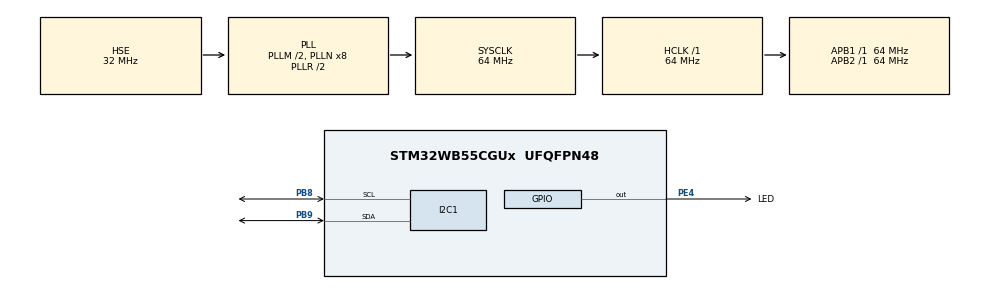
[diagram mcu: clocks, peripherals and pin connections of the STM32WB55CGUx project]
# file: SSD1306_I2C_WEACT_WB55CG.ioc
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Dma.I2C1_TX.0.Direction=DMA_MEMORY_TO_PERIPH
Dma.I2C1_TX.0.EventEnable=DISABLE
Dma.I2C1_TX.0.Instance=DMA1_Channel6
Dma.I2C1_TX.0.MemDataAlignment=DMA_MDATAALIGN_BYTE
Dma.I2C1_TX.0.MemInc=DMA_MINC_ENABLE
Dma.I2C1_TX.0.Mode=DMA_NORMAL
Dma.I2C1_TX.0.PeriphDataAlignment=DMA_PDATAALIGN_BYTE
Dma.I2C1_TX.0.PeriphInc=DMA_PINC_DISABLE
Dma.I2C1_TX.0.Polarity=HAL_DMAMUX_REQ_GEN_RISING
Dma.I2C1_TX.0.Priority=DMA_PRIORITY_LOW
Dma.I2C1_TX.0.RequestNumber=1
Dma.I2C1_TX.0.SignalID=NONE
Dma.I2C1_TX.0.SyncEnable=DISABLE
Dma.I2C1_TX.0.SyncPolarity=HAL_DMAMUX_SYNC_NO_EVENT
Dma.I2C1_TX.0.SyncRequestNumber=1
Dma.I2C1_TX.0.SyncSignalID=NONE
Dma.Request0=I2C1_TX
I2C1.Timing=0x10B17DB5
Mcu.Family=STM32WB
Mcu.Name=STM32WB55CGUx
Mcu.Package=UFQFPN48
NVIC.DMA1_Channel6_IRQn=true\:0\:0\:false\:false\:true\:false\:true\:true
NVIC.I2C1_EV_IRQn=true\:0\:0\:false\:false\:true\:true\:true\:true
NVIC.PriorityGroup=NVIC_PRIORITYGROUP_4
NVIC.TIM2_IRQn=true\:15\:0\:false\:false\:true\:false\:true\:true
NVIC.TimeBase=TIM2_IRQn
NVIC.TimeBaseIP=TIM2
OSC_IN.Mode=HSE-External-Oscillator
OSC_IN.Signal=RCC_OSC_IN
OSC_OUT.Mode=HSE-External-Oscillator
OSC_OUT.Signal=RCC_OSC_OUT
PB8.GPIO_Speed=GPIO_SPEED_FREQ_VERY_HIGH
PB8.Mode=I2C
PB8.Signal=I2C1_SCL
PB9.GPIO_Speed=GPIO_SPEED_FREQ_VERY_HIGH
PB9.Mode=I2C
PB9.Signal=I2C1_SDA
PC14-OSC32_IN.Mode=LSE-External-Oscillator
PC14-OSC32_IN.Signal=RCC_OSC32_IN
PC15-OSC32_OUT.Mode=LSE-External-Oscillator
PC15-OSC32_OUT.Signal=RCC_OSC32_OUT
PE4.GPIO_Label=LED
PE4.Signal=GPIO_Output
ProjectManager.HeapSize=0x200
ProjectManager.StackSize=0x400
ProjectManager.TargetToolchain=STM32CubeIDE
RCC.ADCFreq_Value=64000000
RCC.AHB2CLKDivider=RCC_SYSCLK_DIV2
RCC.AHBFreq_Value=64000000
RCC.APB1Freq_Value=64000000
RCC.APB1TimFreq_Value=64000000
RCC.APB2Freq_Value=64000000
RCC.APB2TimFreq_Value=64000000
RCC.APB3Freq_Value=16000000
RCC.Cortex2_Div=SYSTICK_CLKSOURCE_HCLK_DIV8
RCC.CortexFreq_Value=64000000
RCC.HCLKFreq_Value=64000000
RCC.HSE_VALUE=32000000
RCC.HSI48_VALUE=48000000
RCC.HSI_VALUE=16000000
RCC.PLLM=RCC_PLLM_DIV2
RCC.PLLSourceVirtual=RCC_PLLSOURCE_HSE
RCC.RTCClockSelection=RCC_RTCCLKSOURCE_LSE
RCC.SYSCLKFreq_VALUE=64000000
RCC.SYSCLKSource=RCC_SYSCLKSOURCE_PLLCLK
RCC.USBFreq_Value=64000000
RCC.VCOOutputFreq_Value=128000000
RTC.Date=20
RTC.Hours=1
RTC.Minutes=15
RTC.Month=RTC_MONTH_JUNE
RTC.WeekDay=RTC_WEEKDAY_SATURDAY
RTC.Year=26
VP_MEMORYMAP_VS_MEMORYMAP.Mode=CurAppReg
VP_RTC_VS_RTC_Activate.Mode=RTC_Enabled
VP_RTC_VS_RTC_Calendar.Mode=RTC_Calendar
VP_SYS_VS_tim2.Mode=TIM2
board=custom

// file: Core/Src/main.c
/* USER CODE BEGIN Header */
/**
  ******************************************************************************
  * @file           : main.c
  * @brief          : Main program body
  ******************************************************************************
  * @attention
  *
  * Copyright (c) 2026 STMicroelectronics.
  * All rights reserved.
  *
  * This software is licensed under terms that can be found in the LICENSE file
  * in the root directory of this software component.
  * If no LICENSE file comes with this software, it is provided AS-IS.
  *
  ******************************************************************************
  */
/* USER CODE END Header */
#include "main.h"

/* USER CODE BEGIN Includes */
#include <stdio.h>
#include "ssd1306.h"
/* USER CODE END Includes */

/* USER CODE BEGIN PD */
volatile uint8_t rast = 0;
/* USER CODE END PD */

I2C_HandleTypeDef hi2c1;
DMA_HandleTypeDef hdma_i2c1_tx;

RTC_HandleTypeDef hrtc;

void SystemClock_Config(void);
void PeriphCommonClock_Config(void);
static void MX_GPIO_Init(void);
static void MX_DMA_Init(void);
static void MX_I2C1_Init(void);
static void MX_RTC_Init(void);
/* USER CODE BEGIN PFP */
void ssd1306_RasterIntCallback(uint8_t r);
static void LED_Blink(uint32_t Hdelay,uint32_t Ldelay);
/* USER CODE END PFP */

int main(void)
{

  /* MCU Configuration--------------------------------------------------------*/

  /* Reset of all peripherals, Initializes the Flash interface and the Systick. */
  HAL_Init();

  /* Configure the system clock */
  SystemClock_Config();

  /* Configure the peripherals common clocks */
  PeriphCommonClock_Config();

  /* Initialize all configured peripherals */
  MX_GPIO_Init();
  MX_DMA_Init();
  MX_I2C1_Init();
  MX_RTC_Init();

  /* Infinite loop */
  /* USER CODE BEGIN WHILE */
  ssd1306_Init();

  // ------ Text Demo ------
  ssd1306_Clear();

  ssd1306_SetColor(White);

  ssd1306_SetCursor(0, 0);
  ssd1306_WriteString("SSD1306 DEMO", Font_7x10);

  ssd1306_SetCursor(0, 16);
  ssd1306_WriteString("Hello World!", Font_7x10);

  ssd1306_SetCursor(0, 32);
  ssd1306_WriteString("STM32 OLED", Font_7x10);

  ssd1306_UpdateScreen();

  HAL_Delay(1000);

  // ------ Shape Demo ------
  ssd1306_Clear();
  ssd1306_SetColor(White);

  // Rectangle outline
  ssd1306_DrawRect(2, 2, 40, 20);

  // Filled rectangle
  ssd1306_FillRect(50, 2, 40, 20);

  // Circle
  ssd1306_DrawCircle(30, 50, 10);

  // Filled circle
  ssd1306_FillCircle(90, 50, 10);

  // Triangle
  ssd1306_DrawTriangle(10, 60, 30, 40, 50, 60);

  ssd1306_UpdateScreen();

  HAL_Delay(1000);

  // ----- Line Demo ------
  ssd1306_Clear();
  ssd1306_SetColor(White);

  // Horizontal line
  ssd1306_DrawHorizontalLine(0, 10, 128);

  // Vertical line
  ssd1306_DrawVerticalLine(64, 0, 64);

  // Diagonal line
  ssd1306_DrawLine(0, 63, 127, 0);

  ssd1306_UpdateScreen();

  HAL_Delay(1000);

  // ----- Animation ------
  ssd1306_Clear();
  ssd1306_SetColor(White);

  for (uint8_t i = 0; i <= 100; i++)
  {
      // progress bar di tengah layar
      ssd1306_DrawProgressBar(10, 18, 108, 8, i);

      ssd1306_SetCursor(55, 4);

      char buf[10];
      sprintf(buf, "%d%%", i);
      ssd1306_WriteString(buf, Font_7x10);

      ssd1306_UpdateScreen();
      HAL_Delay(30);
  }

  while (1)
  {
    /* USER CODE END WHILE */

    /* USER CODE BEGIN 3 */
	LED_Blink(3,500);
  }
  /* USER CODE END 3 */
}

void SystemClock_Config(void)
{
  RCC_OscInitTypeDef RCC_OscInitStruct = {0};
  RCC_ClkInitTypeDef RCC_ClkInitStruct = {0};

  /** Configure LSE Drive Capability
  */
  HAL_PWR_EnableBkUpAccess();
  __HAL_RCC_LSEDRIVE_CONFIG(RCC_LSEDRIVE_MEDIUMHIGH);

  /** Configure the main internal regulator output voltage
  */
  __HAL_PWR_VOLTAGESCALING_CONFIG(PWR_REGULATOR_VOLTAGE_SCALE1);

  /** Initializes the RCC Oscillators according to the specified parameters
  * in the RCC_OscInitTypeDef structure.
  */
  RCC_OscInitStruct.OscillatorType = RCC_OSCILLATORTYPE_HSI|RCC_OSCILLATORTYPE_HSE
                              |RCC_OSCILLATORTYPE_LSE;
  RCC_OscInitStruct.HSEState = RCC_HSE_ON;
  RCC_OscInitStruct.LSEState = RCC_LSE_ON;
  RCC_OscInitStruct.HSIState = RCC_HSI_ON;
  RCC_OscInitStruct.HSICalibrationValue = RCC_HSICALIBRATION_DEFAULT;
  RCC_OscInitStruct.PLL.PLLState = RCC_PLL_ON;
  RCC_OscInitStruct.PLL.PLLSource = RCC_PLLSOURCE_HSE;
  RCC_OscInitStruct.PLL.PLLM = RCC_PLLM_DIV2;
  RCC_OscInitStruct.PLL.PLLN = 8;
  RCC_OscInitStruct.PLL.PLLP = RCC_PLLP_DIV2;
  RCC_OscInitStruct.PLL.PLLR = RCC_PLLR_DIV2;
  RCC_OscInitStruct.PLL.PLLQ = RCC_PLLQ_DIV2;
  if (HAL_RCC_OscConfig(&RCC_OscInitStruct) != HAL_OK)
  {
    Error_Handler();
  }

  /** Configure the SYSCLKSource, HCLK, PCLK1 and PCLK2 clocks dividers
  */
  RCC_ClkInitStruct.ClockType = RCC_CLOCKTYPE_HCLK4|RCC_CLOCKTYPE_HCLK2
                              |RCC_CLOCKTYPE_HCLK|RCC_CLOCKTYPE_SYSCLK
                              |RCC_CLOCKTYPE_PCLK1|RCC_CLOCKTYPE_PCLK2;
  RCC_ClkInitStruct.SYSCLKSource = RCC_SYSCLKSOURCE_PLLCLK;
  RCC_ClkInitStruct.AHBCLKDivider = RCC_SYSCLK_DIV1;
  RCC_ClkInitStruct.APB1CLKDivider = RCC_HCLK_DIV1;
  RCC_ClkInitStruct.APB2CLKDivider = RCC_HCLK_DIV1;
  RCC_ClkInitStruct.AHBCLK2Divider = RCC_SYSCLK_DIV2;
  RCC_ClkInitStruct.AHBCLK4Divider = RCC_SYSCLK_DIV1;

  if (HAL_RCC_ClockConfig(&RCC_ClkInitStruct, FLASH_LATENCY_3) != HAL_OK)
  {
    Error_Handler();
  }
}

void PeriphCommonClock_Config(void)
{
  RCC_PeriphCLKInitTypeDef PeriphClkInitStruct = {0};

  /** Initializes the peripherals clock
  */
  PeriphClkInitStruct.PeriphClockSelection = RCC_PERIPHCLK_SMPS;
  PeriphClkInitStruct.SmpsClockSelection = RCC_SMPSCLKSOURCE_HSI;
  PeriphClkInitStruct.SmpsDivSelection = RCC_SMPSCLKDIV_RANGE1;

  if (HAL_RCCEx_PeriphCLKConfig(&PeriphClkInitStruct) != HAL_OK)
  {
    Error_Handler();
  }
}

static void MX_I2C1_Init(void)
{

  hi2c1.Instance = I2C1;
  hi2c1.Init.Timing = 0x10B17DB5;
  hi2c1.Init.OwnAddress1 = 0;
  hi2c1.Init.AddressingMode = I2C_ADDRESSINGMODE_7BIT;
  hi2c1.Init.DualAddressMode = I2C_DUALADDRESS_DISABLE;
  hi2c1.Init.OwnAddress2 = 0;
  hi2c1.Init.OwnAddress2Masks = I2C_OA2_NOMASK;
  hi2c1.Init.GeneralCallMode = I2C_GENERALCALL_DISABLE;
  hi2c1.Init.NoStretchMode = I2C_NOSTRETCH_DISABLE;
  if (HAL_I2C_Init(&hi2c1) != HAL_OK)
  {
    Error_Handler();
  }

  /** Configure Analogue filter
  */
  if (HAL_I2CEx_ConfigAnalogFilter(&hi2c1, I2C_ANALOGFILTER_ENABLE) != HAL_OK)
  {
    Error_Handler();
  }

  /** Configure Digital filter
  */
  if (HAL_I2CEx_ConfigDigitalFilter(&hi2c1, 0) != HAL_OK)
  {
    Error_Handler();
  }

}

static void MX_RTC_Init(void)
{

  RTC_TimeTypeDef sTime = {0};
  RTC_DateTypeDef sDate = {0};

  /** Initialize RTC Only
  */
  hrtc.Instance = RTC;
  hrtc.Init.HourFormat = RTC_HOURFORMAT_24;
  hrtc.Init.AsynchPrediv = 127;
  hrtc.Init.SynchPrediv = 255;
  hrtc.Init.OutPut = RTC_OUTPUT_DISABLE;
  hrtc.Init.OutPutPolarity = RTC_OUTPUT_POLARITY_HIGH;
  hrtc.Init.OutPutType = RTC_OUTPUT_TYPE_OPENDRAIN;
  hrtc.Init.OutPutRemap = RTC_OUTPUT_REMAP_NONE;
  if (HAL_RTC_Init(&hrtc) != HAL_OK)
  {
    Error_Handler();
  }

  /** Initialize RTC and set the Time and Date
  */
  sTime.Hours = 0x1;
  sTime.Minutes = 0x15;
  sTime.Seconds = 0x0;
  sTime.SubSeconds = 0x0;
  sTime.DayLightSaving = RTC_DAYLIGHTSAVING_NONE;
  sTime.StoreOperation = RTC_STOREOPERATION_RESET;
  if (HAL_RTC_SetTime(&hrtc, &sTime, RTC_FORMAT_BCD) != HAL_OK)
  {
    Error_Handler();
  }
  sDate.WeekDay = RTC_WEEKDAY_SATURDAY;
  sDate.Month = RTC_MONTH_JUNE;
  sDate.Date = 0x20;
  sDate.Year = 0x26;

  if (HAL_RTC_SetDate(&hrtc, &sDate, RTC_FORMAT_BCD) != HAL_OK)
  {
    Error_Handler();
  }

}

static void MX_DMA_Init(void)
{

  /* DMA controller clock enable */
  __HAL_RCC_DMAMUX1_CLK_ENABLE();
  __HAL_RCC_DMA1_CLK_ENABLE();

  /* DMA interrupt init */
  /* DMA1_Channel6_IRQn interrupt configuration */
  HAL_NVIC_SetPriority(DMA1_Channel6_IRQn, 0, 0);
  HAL_NVIC_EnableIRQ(DMA1_Channel6_IRQn);

}

static void MX_GPIO_Init(void)
{
  GPIO_InitTypeDef GPIO_InitStruct = {0};

  /* GPIO Ports Clock Enable */
  __HAL_RCC_GPIOC_CLK_ENABLE();
  __HAL_RCC_GPIOB_CLK_ENABLE();
  __HAL_RCC_GPIOE_CLK_ENABLE();

  /*Configure GPIO pin Output Level */
  HAL_GPIO_WritePin(LED_GPIO_Port, LED_Pin, GPIO_PIN_RESET);

  /*Configure GPIO pin : LED_Pin */
  GPIO_InitStruct.Pin = LED_Pin;
  GPIO_InitStruct.Mode = GPIO_MODE_OUTPUT_PP;
  GPIO_InitStruct.Pull = GPIO_NOPULL;
  GPIO_InitStruct.Speed = GPIO_SPEED_FREQ_LOW;
  HAL_GPIO_Init(LED_GPIO_Port, &GPIO_InitStruct);

}

/* USER CODE BEGIN 4 */
void ssd1306_RasterIntCallback(uint8_t r)
{
  if(r == 1)
  {
    ssd1306_SetColor(Black);
    ssd1306_Fill();
  }

  else if(r == 2)
  {
    ssd1306_SetColor(White);
    ssd1306_Fill();
  }
}
static void LED_Blink(uint32_t Hdelay,uint32_t Ldelay)
{
	HAL_GPIO_WritePin(LED_GPIO_Port,LED_Pin,GPIO_PIN_SET);
	HAL_Delay(Hdelay - 1);
	HAL_GPIO_WritePin(LED_GPIO_Port,LED_Pin,GPIO_PIN_RESET);
	HAL_Delay(Ldelay-1);
}
/* USER CODE END 4 */

void HAL_TIM_PeriodElapsedCallback(TIM_HandleTypeDef *htim)
{
  if (htim->Instance == TIM2)
  {
    HAL_IncTick();
  }
}

void Error_Handler(void)
{
  __disable_irq();
  while (1)
  {
  }
}
